# S32K324_M7 register map
Vendor: NXP Semiconductors; File version: 1.1
CPU: CM7 r0p1, little endian, MPU, FPU, VTOR, 4 interrupt priority bits
Registers are 32-bit, read-write, reset 0x0 unless marked. A register's access mark holds for its fields unless they carry their own. Offsets are from the block's base; [hi:lo] are bit positions; {n}, {i} and the like mark numbered series; 'fields as' and 'values as' point back to an identical list.

## LPCMP_0 — LPCMP
Base 0x40370000
Same registers: LPCMP_1 0x40374000, LPCMP_2 0x404E8000
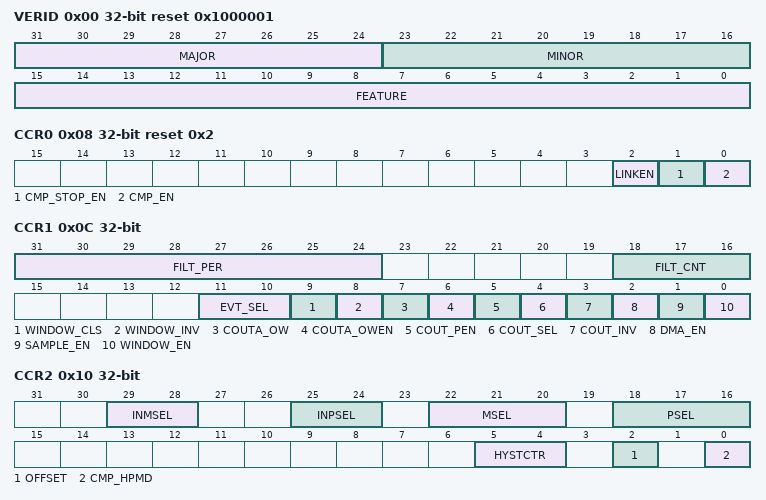
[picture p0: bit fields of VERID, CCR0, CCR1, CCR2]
0x00 VERID ro reset 0x1000001 — Version ID Register
  [31:24] MAJOR — Major Version Number
  [23:16] MINOR — Minor Version Number
  [15:0] FEATURE — Feature Specification Number
    1=ROUND_ROBIN (Round robin feature)
0x04 PARAM ro reset 0x2 — Parameter Register
  [3:0] DAC_RES — DAC Resolution
    0=RESO_4 (4 bit DAC); 1=RESO_6 (6 bit DAC); 2=RESO_8 (8 bit DAC); 3=RESO_10 (10 bit DAC); 4=RESO_12 (12 bit DAC); 5=RESO_14 (14 bit DAC); 6=RESO_16 (16 bit DAC)
0x08 CCR0 reset 0x2 — Comparator Control Register 0
  [2] LINKEN — CMP-to-DAC Link Enable
    0=DISABLE (Disable the CMP-to-DAC link: enabling or disabling the DAC is independent from enabling or disabling the CMP.); 1=ENABLE (Enable the CMP-to-DAC link: the DAC enable/disable is controlled by the CMP_EN bit instead of DCR[DAC_EN]. Also, when the CMP is auto-disabled because software selects the same signal for both the plus and minus comparator inputs, the DAC is disabled too.)
  [1] CMP_STOP_EN — Comparator STANDBY Mode Enable
    0=DISABLE (Disable the analog comparator regardless of CMP_EN.); 1=ENABLE (Allow the analog comparator to be enabled by CMP_EN.)
  [0] CMP_EN — Comparator Enable
    0=DISABLE (Disable (The analog logic remains off and consumes no power.)); 1=ENABLE
0x0C CCR1 — Comparator Control Register 1
  [31:24] FILT_PER — Filter Sample Period
  [18:16] FILT_CNT — Filter Sample Count
    0=BYPASSED (Filter is bypassed: COUT = COUTA); 1=SAMPLE_1 (1 consecutive sample (Comparator output is simply sampled.)); {v}=SAMPLE_{v} ({v} consecutive samples) (v=2..7)
  [11:10] EVT_SEL — CMPO Event Select
    0=RISING (Rising edge); 1=FALLING (Falling edge); 0b1x=BOTH (Both edges)
  [9] WINDOW_CLS — CMPO Event Window Close
    0=NO_CLOSE (CMPO event cannot close the window); 1=CLOSE (CMPO event can close the window)
  [8] WINDOW_INV — WINDOW/SAMPLE Signal Invert
    0=NO_INVERT (Do not invert); 1=INVERT
  [7] COUTA_OW — COUTA Output Level for Closed Window
    0=COUTA_0 (COUTA is 0); 1=COUTA_1 (COUTA is 1)
  [6] COUTA_OWEN — COUTA_OW Enable
    0=SAMPLED (COUTA holds the last sampled value); 1=COUTA_OW (COUTA is defined by the COUTA_OW bit)
  [5] COUT_PEN — Comparator Output Pin Enable
    0=UNAVAILABLE (Not available); 1=AVAILABLE
  [4] COUT_SEL — Comparator Output Select
    0=COUT (Use COUT (filtered)); 1=COUTA (Use COUTA (unfiltered))
  [3] COUT_INV — Comparator Invert
    0=NO_INVERT (Do not invert); 1=INVERT
  [2] DMA_EN — DMA Enable
    0=DISABLE; 1=ENABLE
  [1] SAMPLE_EN — Sampling Enable
    0=DISABLE; 1=ENABLE
  [0] WINDOW_EN — Windowing Enable
    0=DISABLE; 1=ENABLE
0x10 CCR2 — Comparator Control Register 2
  [29:28] INMSEL — Input Minus Select
    0=IN0 (IN0: from the 8-bit DAC output); 1=IN1 (IN1: from the analog 8-1 mux)
  [25:24] INPSEL — Input Plus Select
    values as INMSEL
  [22:20] MSEL — Minus Input MUX Select
    {v}=INPUT_{v} (v=0..7)
  [18:16] PSEL — Plus Input MUX Select
    {v}=INPUT_{v} (v=0..7)
  [5:4] HYSTCTR — Comparator Hysteresis Control
    {v}=LEVEL_{v} (v=0..3)
  [2] OFFSET — Comparator Offset Control
    0=LEVEL_0 (Level 0: The hysteresis selected by HYSTCTR is valid for both directions (rising and falling).); 1=LEVEL_1 (Level 1: Hysteresis does not apply when INP (input-plus) crosses INM (input-minus) in the rising direction or when INM crosses INP in the falling direction. Hysteresis still applies for INP crossing INM in the falling direction.)
  [0] CMP_HPMD — CMP High Power Mode Select
    0=LOW (Low power(speed) comparison mode); 1=HIGH (High power(speed) comparison mode)
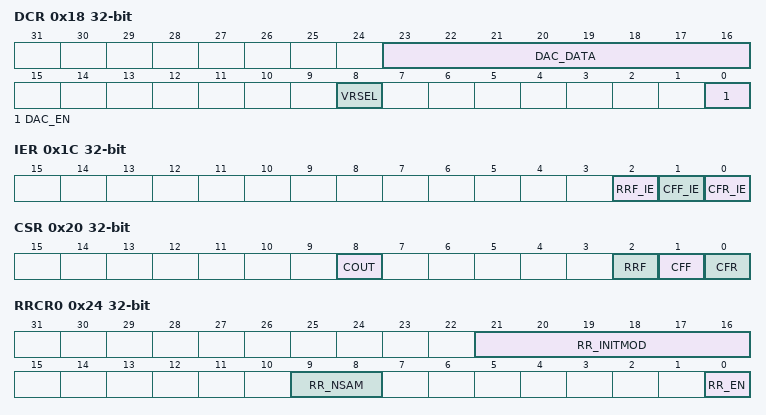
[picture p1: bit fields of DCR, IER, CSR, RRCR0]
0x18 DCR — DAC Control Register
  [23:16] DAC_DATA — DAC Output Voltage Select
  [8] VRSEL — DAC Reference High Voltage Source Select
    0=VREF0 (vrefh0); 1=VREF1 (vrefh1)
  [0] DAC_EN — DAC Enable
    0=DISABLE; 1=ENABLE
0x1C IER — Interrupt Enable Register
  [2] RRF_IE — Round-Robin Flag Interrupt Enable
    0=DISABLE; 1=ENABLE (Enable: Assert an interrupt when the comparison result changes for a given channel.)
  [1] CFF_IE — Comparator Flag Falling Interrupt Enable
    0=DISABLE; 1=ENABLE (Enable: Assert an interrupt when CFF is set.)
  [0] CFR_IE — Comparator Flag Rising Interrupt Enable
    0=DISABLE; 1=ENABLE (Enable: Assert an interrupt when CFR is set.)
0x20 CSR — Comparator Status Register
  [8] COUT ro — Analog Comparator Output
  [2] RRF write-1-clears — Round-Robin Flag
    0=NOT_DETECTED; 1=DETECTED
  [1] CFF write-1-clears — Analog Comparator Flag Falling
    0=NOT_DETECTED; 1=DETECTED
  [0] CFR write-1-clears — Analog Comparator Flag Rising
    0=NOT_DETECTED; 1=DETECTED
0x24 RRCR0 — Round Robin Control Register 0
  [21:16] RR_INITMOD — Initialization Delay Modulus
    0=MOD_63 (63 cycles (same as 111111b)); {v}=MOD_1_63 (1 to 63 cycles) (v=1..9)
  [9:8] RR_NSAM — Number of Sample Clocks
    {v}=WAIT_{v} ({v} clocks) (v=0..3)
  [0] RR_EN — Round-Robin Enable
    0=DISABLE; 1=ENABLE
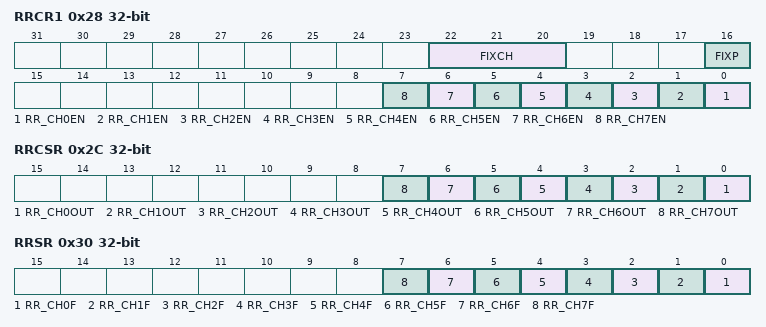
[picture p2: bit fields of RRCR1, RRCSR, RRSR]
0x28 RRCR1 — Round Robin Control Register 1
  [22:20] FIXCH — Fixed Channel Select
    {v}=FIX_CH{v} (Channel {v}) (v=0..7)
  [16] FIXP — Fixed Port
    0=FIX_PLUS (Fix the Plus port. Sweep only the inputs to the Minus port.); 1=FIX_MINUS (Fix the Minus port. Sweep only the inputs to the Plus port.)
  [n] RR_CH{n}EN (n=0..7) — Channel {n} Input Enable in Trigger Mode
    0=DISABLE; 1=ENABLE
0x2C RRCSR — Round Robin Control and Status Register
  [n] RR_CH{n}OUT (n=0..7) — Comparison Result for Channel {n}
0x30 RRSR write-1-clears — Round Robin Status Register
  [all] fields
    0=NOT_DIFFERENT; 1=DIFFERENT
  [n] RR_CH{n}F write-1-clears (n=0..7) — Channel {n} Input Changed Flag
